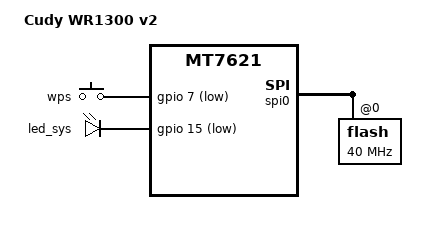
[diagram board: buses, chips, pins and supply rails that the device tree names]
// SPDX-License-Identifier: GPL-2.0-or-later OR MIT

#include "mt7621_cudy_wr1300.dtsi"

/ {
	compatible = "cudy,wr1300-v2", "mediatek,mt7621-soc";
	model = "Cudy WR1300 v2";

	keys {
		wps {
			gpios = <&gpio 7 GPIO_ACTIVE_LOW>;
		};
	};
};

&led_sys {
	gpios = <&gpio 15 GPIO_ACTIVE_LOW>;
};

&spi0 {
	flash@0 {
		spi-max-frequency = <40000000>;
	};
};
